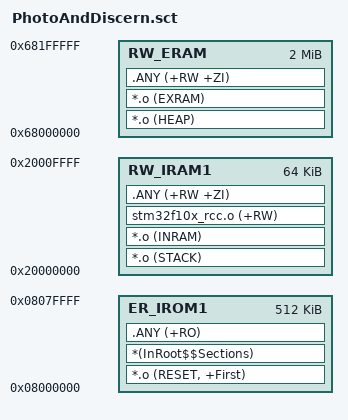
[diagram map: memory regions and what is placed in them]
; *************************************************************
; *** Scatter-Loading Description File generated by uVision ***
; *************************************************************

LR_IROM1 0x08000000 0x00080000  {    ; load region size_region
  ER_IROM1 0x08000000 0x00080000  {  ; load address = execution address
   *.o (RESET, +First)
   *(InRoot$$Sections)
   .ANY (+RO)
  }
  RW_IRAM1 0x20000000 0x00010000  {  ; RW data
   *.o (STACK)  
   *.o (INRAM)
   stm32f10x_rcc.o (+RW)
   .ANY (+RW +ZI)
  }
   RW_ERAM 0x68000000 0x00200000  {  ; RW data
   *.o (HEAP)
   *.o (EXRAM)  
   .ANY (+RW +ZI)
  }
}

